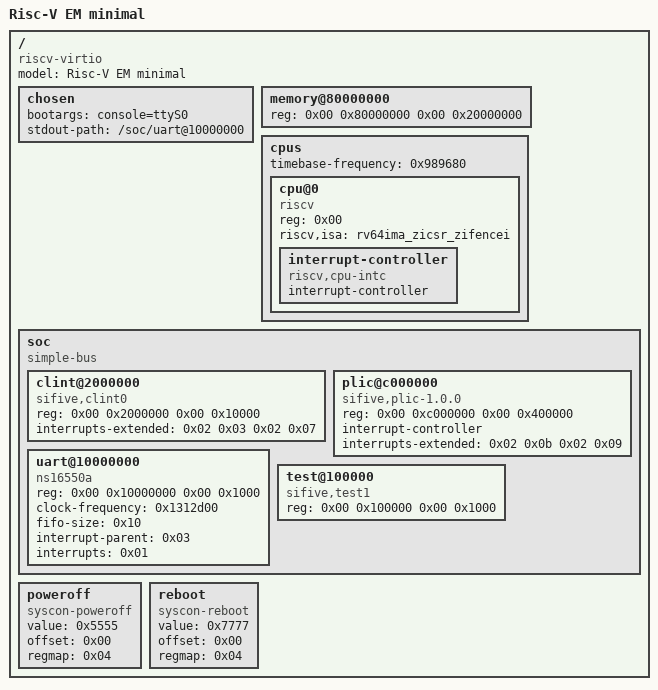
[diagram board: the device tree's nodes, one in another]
/dts-v1/;

/ {
    #address-cells = <2>;
    #size-cells = <2>;
    model = "Risc-V EM minimal";
    compatible = "riscv-virtio", "simple-bus";

    chosen {
        bootargs = "console=ttyS0";
        stdout-path = "/soc/uart@10000000";
    };

    memory@80000000 {
        device_type = "memory";
        reg = <0x00 0x80000000 0x00 0x20000000>;  // 512MB
    };

    cpus {
        #address-cells = <1>;
        #size-cells = <0>;
        timebase-frequency = <0x989680>;

        cpu@0 {
            device_type = "cpu";
            reg = <0x00>;
            compatible = "riscv";
            status = "okay";
            riscv,isa = "rv64ima_zicsr_zifencei";
            phandle = <0x01>;

            interrupt-controller {
                #interrupt-cells = <1>;
                interrupt-controller;
                compatible = "riscv,cpu-intc";
                phandle = <0x02>;
            };
        };
    };

    soc {
        #address-cells = <2>;
        #size-cells = <2>;
        compatible = "simple-bus";
        ranges;

        clint@2000000 {
            reg = <0x00 0x2000000 0x00 0x10000>;
            compatible = "sifive,clint0", "riscv,clint0";
            interrupts-extended = <0x02 0x03 0x02 0x07>;
        };

        plic@c000000 {
            reg = <0x00 0xc000000 0x00 0x400000>;
            compatible = "sifive,plic-1.0.0";
            interrupt-controller;
            #interrupt-cells = <1>;
            #address-cells = <0>;
            interrupts-extended = <0x02 0x0b 0x02 0x09>;
            phandle = <0x03>;
        };

        uart@10000000 {
            reg = <0x00 0x10000000 0x00 0x1000>;
            compatible = "ns16550a";
            clock-frequency = <0x1312d00>;
            fifo-size = <0x10>;
            status = "okay";
            interrupt-parent = <0x03>;
            interrupts = <0x01>;
        };

        test@100000 {
            reg = <0x00 0x100000 0x00 0x1000>;
            compatible = "sifive,test1", "sifive,test0", "syscon";
            phandle = <0x04>;
        };
    };

    poweroff {
        compatible = "syscon-poweroff";
        value = <0x5555>;
        offset = <0x00>;
        regmap = <0x04>;
    };

    reboot {
        compatible = "syscon-reboot";
        value = <0x7777>;
        offset = <0x00>;
        regmap = <0x04>;
    };
};
